# RTC_C_208.0 register map
Vendor: Texas Instruments
Peripheral module from a debugger description file (folder msp430).
Registers are 16-bit, read-write, no defined reset value unless marked. A register's access mark holds for its fields unless they carry their own. Offsets are as the file gives them; lines under a group give offsets from that group; [hi:lo] are bit positions; {n}, {i} and the like mark numbered series; 'fields as' and 'values as' point back to an identical list; <NAME> marks a mode.

## RTC_C
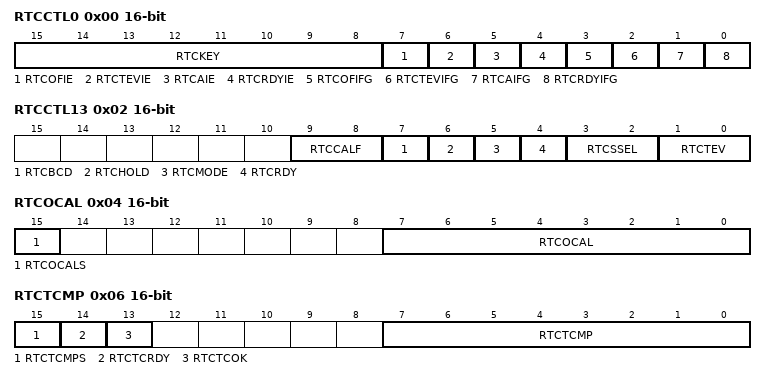
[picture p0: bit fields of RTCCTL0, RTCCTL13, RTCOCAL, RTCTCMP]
0x00 RTCCTL0
  [15:8] RTCKEY — Real-time clock key
  [7] RTCOFIE — 32-kHz crystal oscillator fault interrupt enable
  [6] RTCTEVIE — Real-time clock time event interrupt enable
  [5] RTCAIE — Real-time clock alarm interrupt enable
  [4] RTCRDYIE — Real-time clock ready interrupt enable
  [3] RTCOFIFG — 32-kHz crystal oscillator fault interrupt flag
  [2] RTCTEVIFG — Real-time clock time event interrupt flag
  [1] RTCAIFG — Real-time clock alarm interrupt flag
  [0] RTCRDYIFG — Real-time clock ready interrupt flag
0x02 RTCCTL13 access per field
  [9:8] RTCCALF rw — Real-time clock calibration frequency
    0=NONE (No frequency output to RTCCLK pin); 1=512 Hz; 2=256 Hz; 3=1 Hz
  [7] RTCBCD rw — Real-time clock BCD select
    0=HEX (Binary (hexadecimal) code selected); 1=BCD (Binary coded decimal (BCD) code selected)
  [6] RTCHOLD rw — Real-time clock hold
    0=Real-time clock is operational; 1=When set, the calendar is stopped as well as the prescale counters, RT0PS and RT1PS are don't care
  [5] RTCMODE ro
    1=Calendar mode. Always reads a value of 1.
  [4] RTCRDY ro — Real-time clock ready
    0=RTC time values in transition; 1=RTC time values safe for reading. This bit indicates when the real-time clock time values are safe for reading.
  [3:2] RTCSSEL rw — Real-time clock source select
    0=LFXT (32-kHz crystal oscillator clock); 1=LFXT (32-kHz crystal oscillator clock); 2=RT1PS (Output from RT1PS); 3=RT1PS (Output from RT1PS)
  [1:0] RTCTEV rw — Real-time clock time event
    0=MIN (Minute changed); 1=HOUR (Hour changed); 2=Every day at midnight (00:00); 3=Every day at noon (12:00)
0x04 RTCOCAL
  [15] RTCOCALS — Real-time clock offset error calibration sign
    0=DOWN (Down calibration. Frequency adjusted down.); 1=UP (Up calibration. Frequency adjusted up.)
  [7:0] RTCOCAL — Real-time clock offset error calibration
0x06 RTCTCMP access per field
  [15] RTCTCMPS rw — Real-time clock temperature compensation sign
    0=DOWN (Down calibration. Frequency adjusted down); 1=UP (Up calibration. Frequency adjusted up)
  [14] RTCTCRDY ro — Real-time clock temperature compensation ready
  [13] RTCTCOK ro — Real-time clock temperature compensation write OK
    0=Write to RTCTCMPx is unsuccessful; 1=Write to RTCTCMPx is successful
  [7:0] RTCTCMP rw — Real-time clock temperature compensation
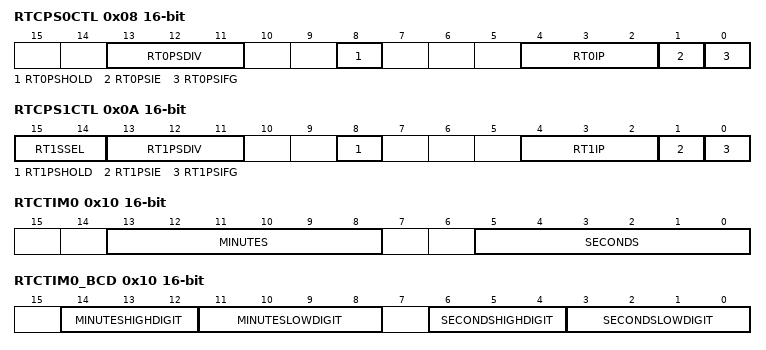
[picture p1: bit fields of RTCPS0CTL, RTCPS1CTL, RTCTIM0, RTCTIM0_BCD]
0x08 RTCPS0CTL — Real-Time Clock Prescale Timer 0 Control Register
  [13:11] RT0PSDIV — Prescale timer 0 clock divide
    0=Divide by 2; 1=Divide by 4; 2=Divide by 8; 3=Divide by 16; 4=Divide by 32; 5=Divide by 64; 6=Divide by 128; 7=Divide by 256
  [8] RT0PSHOLD — Prescale timer 0 hold
    0=RT0PS is operational; 1=RT0PS is held
  [4:2] RT0IP — Prescale timer 0 interrupt interval
    values as RT0PSDIV
  [1] RT0PSIE — Prescale timer 0 interrupt enable
    0=DISABLE (Interrupt not enabled); 1=ENABLE (Interrupt enabled)
  [0] RT0PSIFG — Prescale timer 0 interrupt flag
    0=No time event occurred; 1=Time event occurred
0x0A RTCPS1CTL — Real-Time Clock Prescale Timer 1 Control Register
  [15:14] RT1SSEL — Prescale timer 1 clock source select
    0=32-kHz crystal oscillator clock; 1=32-kHz crystal oscillator clock; 2=RT0PS (Output from RT0PS); 3=RT0PS (Output from RT0PS)
  [13:11] RT1PSDIV — Prescale timer 1 clock divide
    values as RTCPS0CTL.RT0PSDIV
  [8] RT1PSHOLD — Prescale timer 1 hold
    0=RT1PS is operational; 1=RT1PS is held
  [4:2] RT1IP — Prescale timer 1 interrupt interval
    values as RTCPS0CTL.RT0PSDIV
  [1] RT1PSIE — Prescale timer 1 interrupt enable
    0=DISABLE (Interrupt not enabled); 1=ENABLE (Interrupt enabled (LPM3/LPM3.5 wake-up enabled))
  [0] RT1PSIFG — Prescale timer 1 interrupt flag
    0=No time event occurred; 1=Time event occurred
0x0C RTCPS access not given — Real-Time Clock Prescale Timer Counter Register
0x0C RT0PS 8-bit access not given — Prescale timer 0 counter value
0x0D RT1PS 8-bit access not given — Prescale timer 1 counter value
0x0E RTCIV ro — Real-Time Clock Interrupt Vector Register
  [15:0] RTCIV — Real-time clock interrupt vector value
    0=NONE (No interrupt pending); 2=RTCOFIFG (Interrupt Source: RTC oscillator failure; Interrupt Flag: RTCOFIFG; Interrupt Priority: Highest); 4=RTCRDYIFG (Interrupt Source: RTC ready; Interrupt Flag: RTCRDYIFG); 6=RTCTEVIFG (Interrupt Source: RTC interval timer; Interrupt Flag: RTCTEVIFG); 8=RTCAIFG (Interrupt Source: RTC user alarm; Interrupt Flag: RTCAIFG); 10=RT0PSIFG (Interrupt Source: RTC prescaler 0; Interrupt Flag: RT0PSIFG); 12=RT1PSIFG (Interrupt Source: RTC prescaler 1; Interrupt Flag: RT1PSIFG)
0x10 RTCTIM0 — RTCTIM0 Register Hexadecimal Format
  [13:8] MINUTES — Minutes (0 to 59)
  [5:0] SECONDS — Seconds (0 to 59)
0x10 RTCTIM0_BCD — Real-Time Clock Seconds, Minutes Register - BCD Format
  [14:12] MINUTESHIGHDIGIT — Minutes high digit (0 to 5)
  [11:8] MINUTESLOWDIGIT — Minutes low digit (0 to 9)
  [6:4] SECONDSHIGHDIGIT — Seconds high digit (0 to 5)
  [3:0] SECONDSLOWDIGIT — Seconds low digit (0 to 9)
0x10 RTCCNT12 access not given — Real-Time Clock Counter 1 and 2 Register Counter Mode
{0xF+i} RTCCNT{i} 8-bit access not given (i=1..4) — The RTCCNT{i} register is the count of RTCCNT{i}
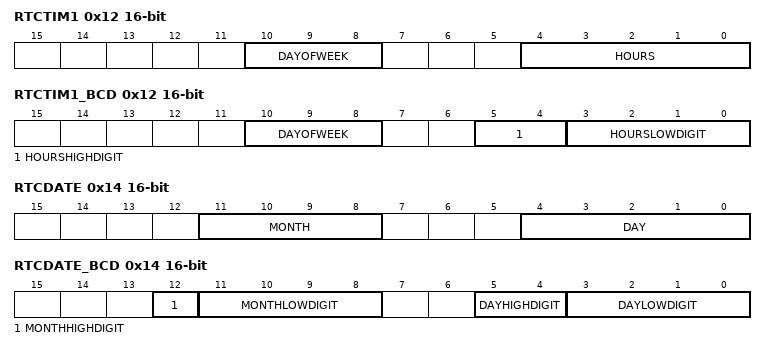
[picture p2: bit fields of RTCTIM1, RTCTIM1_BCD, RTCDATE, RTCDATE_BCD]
0x12 RTCTIM1 — Real-Time Clock Hour, Day of Week
  [10:8] DAYOFWEEK — Day of week (0 to 6)
  [4:0] HOURS — Hours (0 to 23)
0x12 RTCTIM1_BCD — Real-Time Clock Hour, Day of Week - BCD Format
  [10:8] DAYOFWEEK — Day of week (0 to 6)
  [5:4] HOURSHIGHDIGIT — Hours high digit (0 to 2)
  [3:0] HOURSLOWDIGIT — Hours low digit (0 to 9)
0x12 RTCCNT34 access not given — Real-Time Clock Counter 3 and 4 Register Counter Mode
0x14 RTCDATE — RTCDATE - Hexadecimal Format
  [11:8] MONTH — Month (1 to 12)
  [4:0] DAY — Day of month (1 to 28, 29, 30, 31)
0x14 RTCDATE_BCD — Real-Time Clock Date - BCD Format
  [12] MONTHHIGHDIGIT — Month high digit (0 or 1)
  [11:8] MONTHLOWDIGIT — Month low digit (0 to 9)
  [5:4] DAYHIGHDIGIT — Day of month high digit (0 to 3)
  [3:0] DAYLOWDIGIT — Day of month low digit (0 to 9)
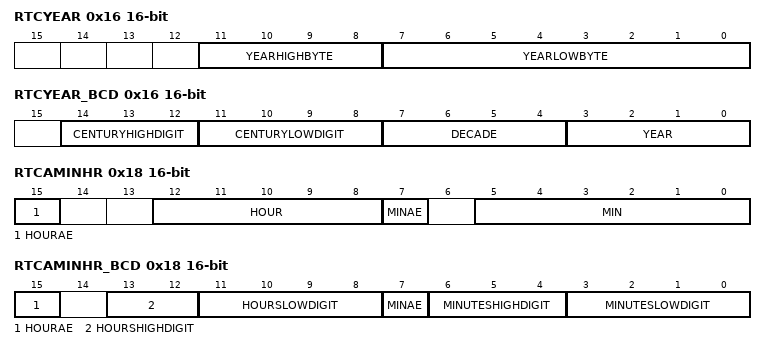
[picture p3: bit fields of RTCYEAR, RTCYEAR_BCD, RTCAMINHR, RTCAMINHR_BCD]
0x16 RTCYEAR — RTCYEAR Register Hexadecimal Format
  [11:8] YEARHIGHBYTE — Year high byte. Valid values for Year are 0 to 4095.
  [7:0] YEARLOWBYTE — Year low byte. Valid values for Year are 0 to 4095.
0x16 RTCYEAR_BCD — Real-Time Clock Year Register - BCD Format
  [14:12] CENTURYHIGHDIGIT — Century high digit (0 to 4)
  [11:8] CENTURYLOWDIGIT — Century low digit (0 to 9)
  [7:4] DECADE — Decade (0 to 9)
  [3:0] YEAR — Year lowest digit (0 to 9)
0x18 RTCAMINHR — RTCMINHR - Hexadecimal Format
  [15] HOURAE — Alarm enable
  [12:8] HOUR — Hours (0 to 23)
  [7] MINAE — Alarm enable
  [5:0] MIN — Minutes (0 to 59)
0x18 RTCAMINHR_BCD — Real-Time Clock Minutes, Hour Alarm - BCD Format
  [15] HOURAE — Alarm enable
  [13:12] HOURSHIGHDIGIT — Hours high digit (0 to 2)
  [11:8] HOURSLOWDIGIT — Hours low digit (0 to 9)
  [7] MINAE — Alarm enable
  [6:4] MINUTESHIGHDIGIT — Minutes high digit (0 to 5)
  [3:0] MINUTESLOWDIGIT — Minutes low digit (0 to 9)
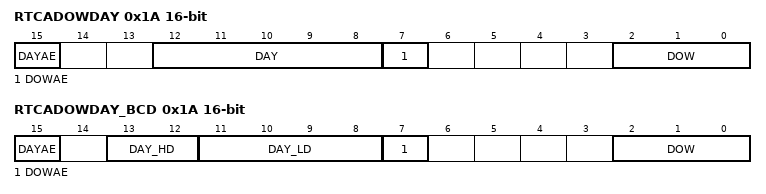
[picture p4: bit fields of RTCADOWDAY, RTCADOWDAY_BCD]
0x1A RTCADOWDAY — RTCADOWDAY - Hexadecimal Format
  [15] DAYAE — Alarm enable
  [12:8] DAY — Day of month (1 to 28, 29, 30, 31)
  [7] DOWAE — Alarm enable
  [2:0] DOW — Day of week (0 to 6)
0x1A RTCADOWDAY_BCD — Real-Time Clock Day of Week, Day of Month Alarm - BCD Format
  [15] DAYAE — Alarm enable
  [13:12] DAY_HD — Day of month high digit (0 to 3)
  [11:8] DAY_LD — Day of month low digit (0 to 9)
  [7] DOWAE — Alarm enable
  [2:0] DOW — Day of week (0 to 6)
0x1C BIN2BCD access not given — Binary-to-BCD Conversion Register
0x1E BCD2BIN access not given — BCD-to-Binary Conversion Register
